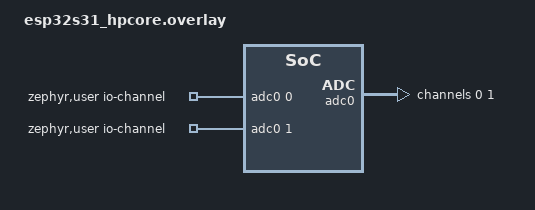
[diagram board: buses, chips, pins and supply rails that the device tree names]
/*
 * Copyright (c) 2026 Espressif Systems (Shanghai) Co., Ltd.
 *
 * SPDX-License-Identifier: Apache-2.0
 */

/ {
	zephyr,user {
		/* ADC1 channels 0 and 1 map to GPIO42/43 on esp32s31 */
		io-channels = <&adc0 0>, <&adc0 1>;
	};
};

&adc0 {
	#address-cells = <1>;
	#size-cells = <0>;
	status = "okay";

	channel@0 {
		reg = <0>;
		zephyr,gain = "ADC_GAIN_1";
		zephyr,reference = "ADC_REF_INTERNAL";
		zephyr,acquisition-time = <ADC_ACQ_TIME_DEFAULT>;
		zephyr,resolution = <17>;
	};

	channel@1 {
		reg = <1>;
		zephyr,gain = "ADC_GAIN_1";
		zephyr,reference = "ADC_REF_INTERNAL";
		zephyr,acquisition-time = <ADC_ACQ_TIME_DEFAULT>;
		zephyr,resolution = <17>;
	};
};
